# CY8C5868AXI_LP035 register map
File version: 0.1
CY8C58LP
Registers are 8-bit, read-write, no defined reset value unless marked. A register's access mark holds for its fields unless they carry their own. Offsets are from the block's base; lines under a group give offsets from that group; [hi:lo] are bit positions; {n}, {i} and the like mark numbered series; 'fields as' and 'values as' point back to an identical list; <NAME> marks a mode.

## Memory map
0x00000000 Timer_Sampling
0x00000000 I2CM_LCD
0x00000000 I2CM_Sequencer

## Timer_Sampling
Base 0x00000000
0x400043A3 Timer_Sampling_GLOBAL_ENABLE — PM.ACT.CFG
  [3:0] en_timer — Enable timer/counters.
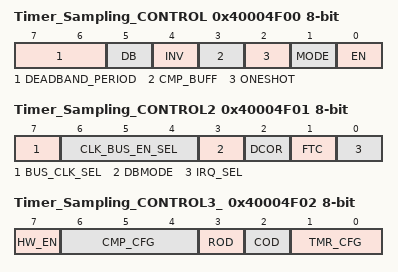
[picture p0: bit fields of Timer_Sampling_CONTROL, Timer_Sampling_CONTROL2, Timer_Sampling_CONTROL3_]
0x40004F00 Timer_Sampling_CONTROL — TMRx.CFG0
  [7:6] DEADBAND_PERIOD
  [5] DB — Deadband mode--Deadband phases phi1 and phi2 are outputted on CMP and TC output pins respectively.
    0=Timer (CMP and TC are output.); 1=Deadband (PHI1 (instead of CMP) and PHI2 (instead of TC) are output.)
  [4] INV — Invert sense of TIMEREN signal
  [3] CMP_BUFF — Buffer compare register. Compare register updates only on timer terminal count.
  [2] ONESHOT — Timer stops upon reaching stop condition defined by TMR_CFG bits. Can be restarted by asserting TIMER RESET or disabling and re-enabling block.
  [1] MODE — Mode. (0 = Timer; 1 = Comparator)
    0=Timer mode. CNT/CMP register holds timer count value.; 1=Comparator mode. CNT/CMP register holds comparator threshold value.
  [0] EN — Enables timer/comparator.
0x40004F01 Timer_Sampling_CONTROL2 — TMRx.CFG1
  [7] BUS_CLK_SEL — Bus Clock selection.
  [6:4] CLK_BUS_EN_SEL — Digital Global Clock selection.
  [3] DBMODE — Deadband mode (asynchronous/synchronous). CMP output pin is also affected when not in deadband mode (CFG0.DEADBAND).
  [2] DCOR — Disable Clear on Read (DCOR) of Status Register SR0.
  [1] FTC — First Terminal Count (FTC). Setting this bit forces a single pulse on the TC pin when first enabled.
    0=Disable_FTC (Disable the single cycle pulse, which signifies the timer is starting.); 1=Enable_FTC (Enable the single cycle pulse, which signifies the timer is starting.)
  [0] IRQ_SEL — Irq selection. (0 = raw interrupts; 1 = status register interrupts)
0x40004F02 Timer_Sampling_CONTROL3_ — TMRx.CFG2
  [7] HW_EN — When set Timer Enable controls counting.
  [6:4] CMP_CFG — Comparator configurations
    0=Equal (Compare Equal); 1=Less_than (Compare Less Than); 2=Less_than_or_equal (Compare Less Than or Equal .); 3=Greater (Compare Greater Than .); 4=Greater_than_or_equal (Compare Greater Than or Equal)
  [3] ROD — Reset On Disable (ROD). Resets internal state of output logic
  [2] COD — Clear On Disable (COD). Clears or gates outputs to zero.
  [1:0] TMR_CFG — Timer configuration (MODE = 0): 000 = Continuous; 001 = Pulsewidth; 010 = Period; 011 = Stop on IRQ
    0=Continuous (Timer runs while EN bit of CFG0 register is set to '1'.); 1=Pulsewidth (Timer runs from positive to negative edge of TIMEREN.); 2=Period (Timer runs from positive to positive edge of TIMEREN.); 3=Irq (Timer runs until IRQ.)
0x40004F04 Timer_Sampling_PERIOD — TMRx.PER0 - Assigned Period
0x40004F06 Timer_Sampling_COUNTER — TMRx.CNT_CMP0 - Current Down Counter Value

## I2CM_LCD
Base 0x00000000
0x40006405 I2CM_LCD_DATA — I2C Data Register
  [7:0] data — Read received data or write data to transmit.
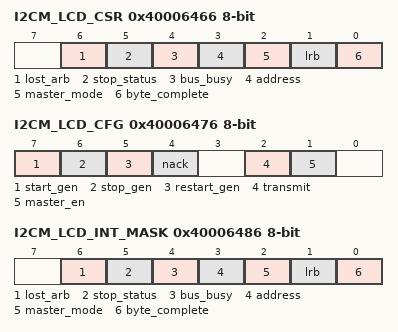
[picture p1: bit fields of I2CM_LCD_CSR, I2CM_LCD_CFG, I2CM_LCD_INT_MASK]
0x40006466 I2CM_LCD_CSR — I2C Status Register
  [6] lost_arb ro — If set, indicates arbitration was lost (multi-master and multi-master-slave modes).
  [5] stop_status ro — If set, indicates a Stop condition was detected on the bus.
  [4] bus_busy ro — If set, indicates the bus is busy. Data is currently being transmitted or received.
  [3] address ro — Address detection. If set, indicates that an address byte was sent.
  [2] master_mode ro — Indicates that a valid Start condition was generated and a hardware device is operating as bus master.
  [1] lrb ro — Last Received Bit. Indicates the state of the last received bit, which is the ACK/NAK received for the last byte transmitted. Cleared = ACK and set = NAK.
  [0] byte_complete ro — Transmit or receive status since the last read of this register. In Transmit mode this bit indicates that eight bits of data plus ACK/NAK have been transmitted since the last read. In Receive mode this bit indicates that eight bits of data have been received since the last read of this register.
0x40006476 I2CM_LCD_CFG — I2C Configuration Register
  [7] start_gen — Set to 1 to generate a Start condition on the bus. This bit must be cleared by firmware before initiating the next transaction.
  [6] stop_gen — Set to 1 to generate a Stop condition on the bus. This bit must be cleared by firmware before initiating the next transaction.
  [5] restart_gen — Set to 1 to generate a Restart condition on the bus. This bit must be cleared by firmware after a Restart condition is generated.
  [4] nack — Set to 1 to NAK the next read byte. Clear to ACK next read byte. This bit must be cleared by firmware between bytes.
  [2] transmit — Set to 1 to set the current mode to transmit or clear to 0 to receive a byte of data. This bit must be cleared by firmware before starting the next transmit or receive transaction.
  [1] master_en — Set to 1 to enable the master functionality.
0x40006486 I2CM_LCD_INT_MASK — I2C Interrupt Enable Mask
  [6] lost_arb — Enables interrupt from the corresponding bit in status register.
  [5] stop_status — Enables interrupt from the corresponding bit in status register.
  [4] bus_busy — Enables interrupt from the corresponding bit in status register.
  [3] address — Enables interrupt from the corresponding bit in status register.
  [2] master_mode — Enables interrupt from the corresponding bit in status register.
  [1] lrb — Enables interrupt from the corresponding bit in status register.
  [0] byte_complete — Enables interrupt from the corresponding bit in status register.

## I2CM_Sequencer
Base 0x00000000
0x40006408 I2CM_Sequencer_DATA — I2C Data Register
  [7:0] data — Read received data or write data to transmit.
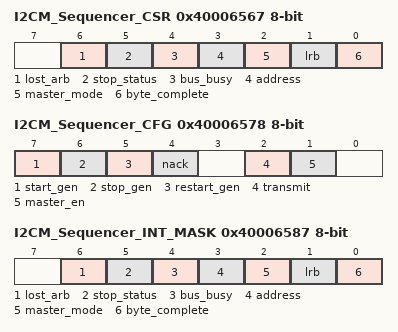
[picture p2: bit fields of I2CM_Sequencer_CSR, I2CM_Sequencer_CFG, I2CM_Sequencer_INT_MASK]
0x40006567 I2CM_Sequencer_CSR — I2C Status Register
  fields as I2CM_LCD.I2CM_LCD_CSR
0x40006578 I2CM_Sequencer_CFG — I2C Configuration Register
  fields as I2CM_LCD.I2CM_LCD_CFG
0x40006587 I2CM_Sequencer_INT_MASK — I2C Interrupt Enable Mask
  fields as I2CM_LCD.I2CM_LCD_INT_MASK
